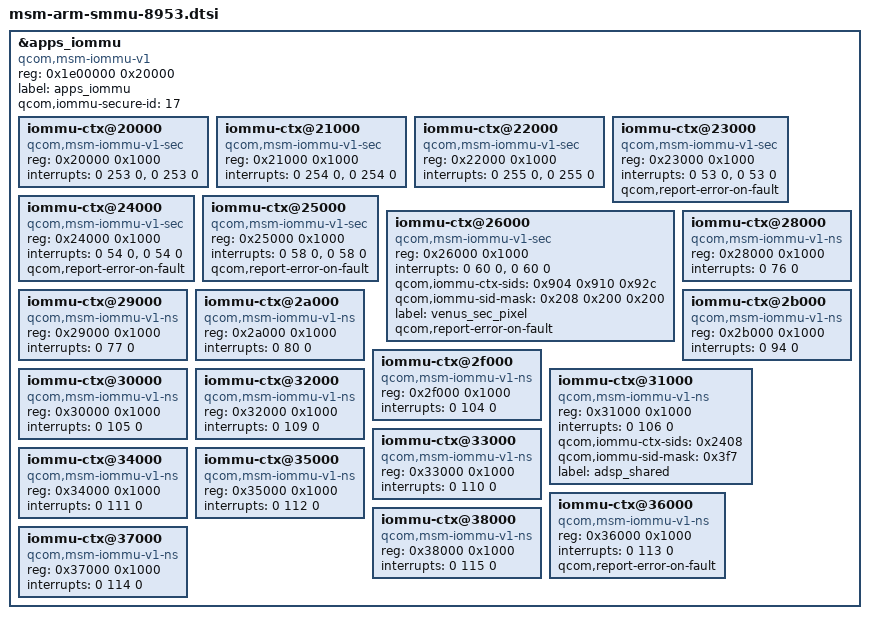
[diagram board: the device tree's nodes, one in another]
/*
 *Copyright (c) 2015-2016, The Linux Foundation. All rights reserved.
 *
 * This program is free software; you can redistribute it and/or modify
 * it under the terms of the GNU General Public License version 2 and
 * only version 2 as published by the Free Software Foundation.
 *
 * This program is distributed in the hope that it will be useful,
 * but WITHOUT ANY WARRANTY; without even the implied warranty of
 * MERCHANTABILITY or FITNESS FOR A PARTICULAR PURPOSE.  See the
 * GNU General Public License for more details.
 */

&apps_iommu {
	/delete-property/ qcom,disable-atos;
	/delete-property/ qcom,enable-static-cb;
	/delete-property/ qcom,skip-init;
	/delete-property/ qcom,tz-device-id;
	/delete-property/ qcom,use-3-lvl-tables;
	/delete-property/ #global-interrupts;

	compatible = "qcom,msm-iommu-v1";
	#address-cells = <1>;
	#size-cells = <1>;
	#iommu-cells = <1>;
	ranges;
	reg = <0x1e00000 0x20000>;
	reg-names = "iommu_base";
        clock-names = "iface", "bus";
	label = "apps_iommu";
	qcom,iommu-secure-id = <17>;
	status = "ok";

	// adsp_elf:
	iommu-ctx@20000 {
		compatible = "qcom,msm-iommu-v1-sec";
		reg = <0x20000 0x1000>;
		interrupts = <0 253 0>, <0 253 0>;
	};

	// adsp_sec_pixel:
	iommu-ctx@21000 {
		compatible = "qcom,msm-iommu-v1-sec";
		reg = <0x21000 0x1000>;
		interrupts = <0 254 0>, <0 254 0>;
	};

	// mdp_1: 
	iommu-ctx@22000 {
		compatible = "qcom,msm-iommu-v1-sec";
		reg = <0x22000 0x1000>;
		interrupts = <0 255 0>, <0 255 0>;
	};

	// venus_fw: 
	iommu-ctx@23000 {
		compatible = "qcom,msm-iommu-v1-sec";
		reg = <0x23000 0x1000>;
		interrupts = <0 53 0>, <0 53 0>;
		qcom,report-error-on-fault;
	};

	// venus_sec_non_pixel:
	iommu-ctx@24000 {
		compatible = "qcom,msm-iommu-v1-sec";
		reg = <0x24000 0x1000>;
		interrupts = <0 54 0>, <0 54 0>;
		qcom,report-error-on-fault;
	};

	// venus_sec_bitstream:
	iommu-ctx@25000 {
		compatible = "qcom,msm-iommu-v1-sec";
		reg = <0x25000 0x1000>;
		interrupts = <0 58 0>, <0 58 0>;
		qcom,report-error-on-fault;
	};

	// venus_sec_pixel:
	iommu-ctx@26000 {
		compatible = "qcom,msm-iommu-v1-sec";
		reg = <0x26000 0x1000>;
		interrupts = <0 60 0>, <0 60 0>;
		qcom,iommu-ctx-sids = <0x904 0x910 0x92c>;
		qcom,iommu-sid-mask = <0x208 0x200 0x200>;
		label = "venus_sec_pixel";
		qcom,report-error-on-fault;
	};

	// pronto_pil:
	iommu-ctx@28000 {
		compatible = "qcom,msm-iommu-v1-ns";
		reg = <0x28000 0x1000>;
		interrupts = <0 76 0>;
	};

	// q6:
	iommu-ctx@29000 {
		compatible = "qcom,msm-iommu-v1-ns";
		reg = <0x29000 0x1000>;
		interrupts = <0 77 0>;
	};

	// periph_rpm:
	iommu-ctx@2a000 {
		compatible = "qcom,msm-iommu-v1-ns";
		reg = <0x2a000 0x1000>;
		interrupts = <0 80 0>;
	};

	// lpass:
	iommu-ctx@2b000 {
		compatible = "qcom,msm-iommu-v1-ns";
		reg = <0x2b000 0x1000>;
		interrupts = <0 94 0>;
	};

	// adsp_io: 
	iommu-ctx@2f000 {
		compatible = "qcom,msm-iommu-v1-ns";
		reg = <0x2f000 0x1000>;
		interrupts = <0 104 0>;
	};

	// adsp_opendsp: 
	iommu-ctx@30000 {
		compatible = "qcom,msm-iommu-v1-ns";
		reg = <0x30000 0x1000>;
		interrupts = <0 105 0>;
	};

	// adsp_shared:
	iommu-ctx@31000 {
		compatible = "qcom,msm-iommu-v1-ns";
		reg = <0x31000 0x1000>;
		interrupts = <0 106 0>;
		qcom,iommu-ctx-sids = <0x2408>;
		qcom,iommu-sid-mask = <0x3f7>;
		label = "adsp_shared";
	};

	// cpp: 
	iommu-ctx@32000 {
		compatible = "qcom,msm-iommu-v1-ns";
		reg = <0x32000 0x1000>;
		interrupts = <0 109 0>;
	};

	// jpeg_enc0: 
	iommu-ctx@33000 {
		compatible = "qcom,msm-iommu-v1-ns";
		reg = <0x33000 0x1000>;
		interrupts = <0 110 0>;
	};

	// vfe: 
	iommu-ctx@34000 {
		compatible = "qcom,msm-iommu-v1-ns";
		reg = <0x34000 0x1000>;
		interrupts = <0 111 0>;
	};

	// mdp_0: 
	iommu-ctx@35000 {
		compatible = "qcom,msm-iommu-v1-ns";
		reg = <0x35000 0x1000>;
		interrupts = <0 112 0>;
	};

	// venus_ns:
	iommu-ctx@36000 {
		compatible = "qcom,msm-iommu-v1-ns";
		reg = <0x36000 0x1000>;
		interrupts = <0 113 0>;
		qcom,report-error-on-fault;
	};

	// ipa:
	iommu-ctx@38000 {
		compatible = "qcom,msm-iommu-v1-ns";
		reg = <0x38000 0x1000>;
		interrupts = <0 115 0>;
	};

	// access_control:
	iommu-ctx@37000 {
		compatible = "qcom,msm-iommu-v1-ns";
		reg = <0x37000 0x1000>;
		interrupts = <0 114 0>;
	};
};
